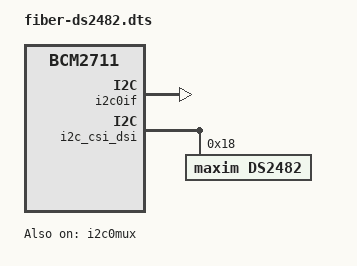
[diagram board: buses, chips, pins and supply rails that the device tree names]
// The DS2482-800 1-Wire master of the FIBER at 0x18, on the CM4's I2C bus of the camera and
// display connectors (i2c_csi_dsi, /dev/i2c-10), which the board uses for its own chips. Enabled
// as the kernel's i2c-rtc overlay enables that bus (i2c0if and i2c0mux). The driver finds the
// eight channels itself: one 1-Wire bus master for each port.
//
// Compiled by provision/release.py: dtc -@ -I dts -O dtb -o fiber-ds2482.dtbo fiber-ds2482.dts
/dts-v1/;
/plugin/;

/ {
	compatible = "brcm,bcm2711";

	fragment@0 {
		target = <&i2c0if>;
		__overlay__ {
			status = "okay";
		};
	};

	fragment@1 {
		target = <&i2c0mux>;
		__overlay__ {
			status = "okay";
		};
	};

	fragment@2 {
		target = <&i2c_csi_dsi>;
		__overlay__ {
			#address-cells = <1>;
			#size-cells = <0>;
			status = "okay";

			ds2482@18 {
				compatible = "maxim,ds2482";
				reg = <0x18>;
			};
		};
	};
};
